# WLR089U0 register map
Vendor: Microchip
Registers are 32-bit, read-write, reset 0x0 unless marked. A register's access mark holds for its fields unless they carry their own. Addresses are absolute, and some are shared; only a register's first bit layout is shown; [hi:lo] are bit positions; {n}, {i} and the like mark numbered series; 'fields as' and 'values as' point back to an identical list.

## TC3
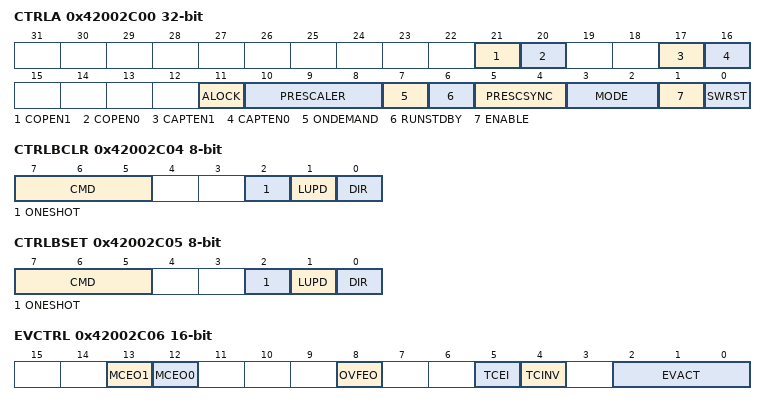
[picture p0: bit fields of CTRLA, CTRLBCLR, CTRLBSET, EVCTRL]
0x42002C00 CTRLA
  [21] COPEN1 — Capture On Pin 1 Enable
  [20] COPEN0 — Capture On Pin 0 Enable
  [17] CAPTEN1 — Capture Channel 1 Enable
  [16] CAPTEN0 — Capture Channel 0 Enable
  [11] ALOCK — Auto Lock
  [10:8] PRESCALER
    0=DIV1 (Prescaler: GCLK_TC); 1=DIV2 (Prescaler: GCLK_TC/2); 2=DIV4 (Prescaler: GCLK_TC/4); 3=DIV8 (Prescaler: GCLK_TC/8); 4=DIV16 (Prescaler: GCLK_TC/16); 5=DIV64 (Prescaler: GCLK_TC/64); 6=DIV256 (Prescaler: GCLK_TC/256); 7=DIV1024 (Prescaler: GCLK_TC/1024)
  [7] ONDEMAND — Clock On Demand
  [6] RUNSTDBY — Run during Standby
  [5:4] PRESCSYNC — Prescaler and Counter Synchronization
    0=GCLK (Reload or reset the counter on next generic clock); 1=PRESC (Reload or reset the counter on next prescaler clock); 2=RESYNC (Reload or reset the counter on next generic clock and reset the prescaler counter)
  [3:2] MODE — Timer Counter Mode
    0=COUNT16 (Counter in 16-bit mode); 1=COUNT8 (Counter in 8-bit mode); 2=COUNT32 (Counter in 32-bit mode)
  [1] ENABLE
  [0] SWRST — Software Reset
0x42002C04 CTRLBCLR 8-bit
  [7:5] CMD — Command
    0=NONE (No action); 1=RETRIGGER (Force a start, restart or retrigger); 2=STOP (Force a stop); 3=UPDATE (Force update of double-buffered register); 4=READSYNC (Force a read synchronization of COUNT); 5=DMAOS (One-shot DMA trigger)
  [2] ONESHOT — One-Shot on Counter
  [1] LUPD — Lock Update
  [0] DIR — Counter Direction
0x42002C05 CTRLBSET 8-bit
  fields as CTRLBCLR
0x42002C06 EVCTRL 16-bit
  [13] MCEO1 — MC Event Output Enable 1
  [12] MCEO0 — MC Event Output Enable 0
  [8] OVFEO — Event Output Enable
  [5] TCEI — TC Event Enable
  [4] TCINV — TC Event Input Polarity
  [2:0] EVACT — Event Action
    0=OFF (Event action disabled); 1=RETRIGGER (Start, restart or retrigger TC on event); 2=COUNT (Count on event); 3=START (Start TC on event); 4=STAMP (Time stamp capture); 5=PPW (Period captured in CC0, pulse width in CC1); 6=PWP (Period captured in CC1, pulse width in CC0); 7=PW (Pulse width capture)
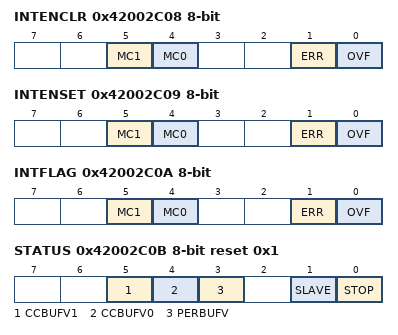
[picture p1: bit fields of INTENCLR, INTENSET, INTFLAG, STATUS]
0x42002C08 INTENCLR 8-bit
  [5] MC1 — MC Interrupt Disable 1
  [4] MC0 — MC Interrupt Disable 0
  [1] ERR — ERR Interrupt Disable
  [0] OVF — OVF Interrupt Disable
0x42002C09 INTENSET 8-bit
  [5] MC1 — MC Interrupt Enable 1
  [4] MC0 — MC Interrupt Enable 0
  [1] ERR — ERR Interrupt Enable
  [0] OVF — OVF Interrupt Enable
0x42002C0A INTFLAG 8-bit
  [5] MC1 — MC Interrupt Flag 1
  [4] MC0 — MC Interrupt Flag 0
  [1] ERR — ERR Interrupt Flag
  [0] OVF — OVF Interrupt Flag
0x42002C0B STATUS 8-bit reset 0x1
  [5] CCBUFV1 — Compare channel buffer 1 valid
  [4] CCBUFV0 — Compare channel buffer 0 valid
  [3] PERBUFV — Synchronization Busy Status
  [1] SLAVE — Slave Status Flag
  [0] STOP — Stop Status Flag
0x42002C0C WAVE 8-bit
  [1:0] WAVEGEN — Waveform Generation Mode
    0=NFRQ (Normal frequency); 1=MFRQ (Match frequency); 2=NPWM (Normal PWM); 3=MPWM (Match PWM)
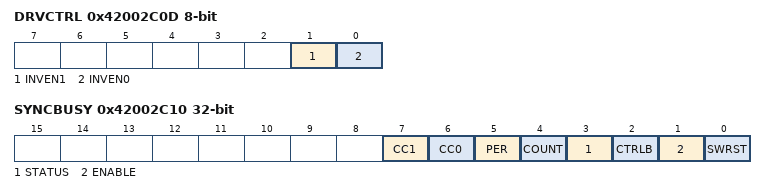
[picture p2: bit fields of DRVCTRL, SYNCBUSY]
0x42002C0D DRVCTRL 8-bit
  [1] INVEN1 — Output Waveform Invert Enable 1
  [0] INVEN0 — Output Waveform Invert Enable 0
0x42002C0F DBGCTRL 8-bit
  [0] DBGRUN — Run During Debug
0x42002C10 SYNCBUSY ro
  [7] CC1 — Compare Channel 1
  [6] CC0 — Compare Channel 0
  [5] PER — Period
  [4] COUNT — Counter
  [3] STATUS
  [2] CTRLB
  [1] ENABLE
  [0] SWRST

## AES
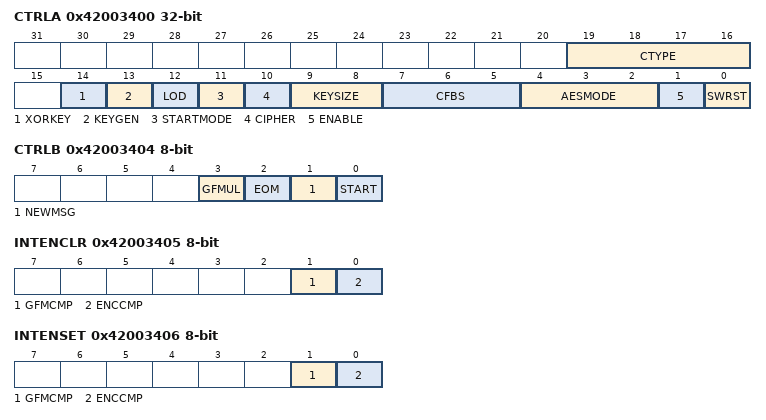
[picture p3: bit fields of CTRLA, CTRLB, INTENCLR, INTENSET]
0x42003400 CTRLA
  [19:16] CTYPE — Counter measure types
  [14] XORKEY — Xor Key operation
  [13] KEYGEN — Last key generation
  [12] LOD — LOD Enable
  [11] STARTMODE
  [10] CIPHER — Cipher mode
  [9:8] KEYSIZE
  [7:5] CFBS — CFB Types
  [4:2] AESMODE — AES Modes of operation
  [1] ENABLE
  [0] SWRST — Software Reset
0x42003404 CTRLB 8-bit
  [3] GFMUL — GF Multiplication
  [2] EOM — End of message
  [1] NEWMSG — New message
  [0] START — Manual Start
0x42003405 INTENCLR 8-bit
  [1] GFMCMP — GF Multiplication Complete
  [0] ENCCMP — Encryption Complete
0x42003406 INTENSET 8-bit
  fields as INTENCLR
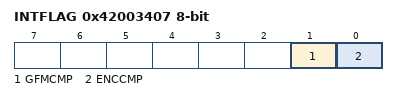
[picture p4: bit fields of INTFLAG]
0x42003407 INTFLAG 8-bit
  fields as INTENCLR
0x42003408 DATABUFPTR 8-bit
  [1:0] INDATAPTR — Input Data Pointer
0x42003409 DBGCTRL 8-bit wo
  [0] DBGRUN — Debug Run
{0x4200340C+4i} KEYWORD{i} wo (i=0..7)
0x42003438 INDATA
{0x4200343C+4i} INTVECTV{i} wo (i=0..3)
{0x4200345C+4i} HASHKEY{i} (i=0..3)
{0x4200346C+4i} GHASH{i} (i=0..3)
0x42003480 CIPLEN
0x42003484 RANDSEED
